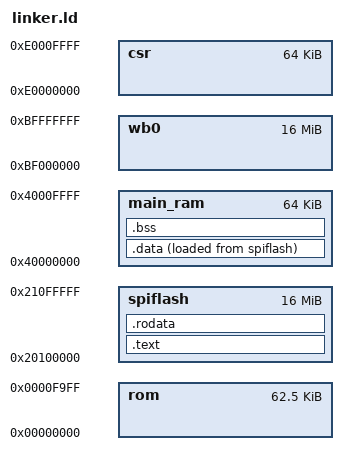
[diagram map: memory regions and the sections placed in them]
OUTPUT_FORMAT("elf32-littleriscv")

ENTRY(_start)

__DYNAMIC = 0;

MEMORY {
	rom : 		ORIGIN = 0x00000000, LENGTH = 0x0000fa00
	spiflash : 	ORIGIN = 0x20100000, LENGTH = 0x01000000
	main_ram : 	ORIGIN = 0x40000000, LENGTH = 0x00010000
	wb0 : 		ORIGIN = 0xbf000000, LENGTH = 0x01000000
	csr : 		ORIGIN = 0xe0000000, LENGTH = 0x00010000
}

SECTIONS
{
	.text :
	{
		_ftext = .;
		/* Make sure crt0 files come first, and they, and the isr */
		/* don't get disposed of by greedy optimisation */
		*crt0*(.text)
		KEEP(*crt0*(.text))
		KEEP(*(.text.isr))

		*(.text .stub .text.* .gnu.linkonce.t.*)
		_etext = .;
	} > spiflash

	.rodata :
	{
		. = ALIGN(8);
		_frodata = .;
		*(.rodata .rodata.* .gnu.linkonce.r.*)
		*(.rodata1)
		*(.got .got.*)
		*(.toc .toc.*)
		. = ALIGN(8);
		_erodata = .;
	} > spiflash

	.data :
	{
		. = ALIGN(8);
		_fdata = .;
		*(.data .data.* .gnu.linkonce.d.*)
		*(.data1)
		_gp = ALIGN(16);
		*(.sdata .sdata.* .gnu.linkonce.s.*)
		. = ALIGN(8);
		_edata = .;
	} > main_ram AT > spiflash

	.bss :
	{
		. = ALIGN(8);
		_fbss = .;
		*(.dynsbss)
		*(.sbss .sbss.* .gnu.linkonce.sb.*)
		*(.scommon)
		*(.dynbss)
		*(.bss .bss.* .gnu.linkonce.b.*)
		*(COMMON)
		. = ALIGN(8);
		_ebss = .;
		_end = .;
	} > main_ram
}

PROVIDE(_fstack = ORIGIN(main_ram) + LENGTH(main_ram));

PROVIDE(_fdata_rom = LOADADDR(.data));
PROVIDE(_edata_rom = LOADADDR(.data) + SIZEOF(.data));
